VERSION ""

NS_ :

BS_:

BU_:

BO_ 933 DRIVE_SP: 2 Vector__XXX
	SG_ speed_sp : 0|16@1- (1,0) [0|31402] "cmd" Vector__XXX

BO_ 934 STEER_SP: 2 Vector__XXX
	SG_ speed_sp : 0|16@1- (1,0) [0|31402] "cmd" Vector__XXX

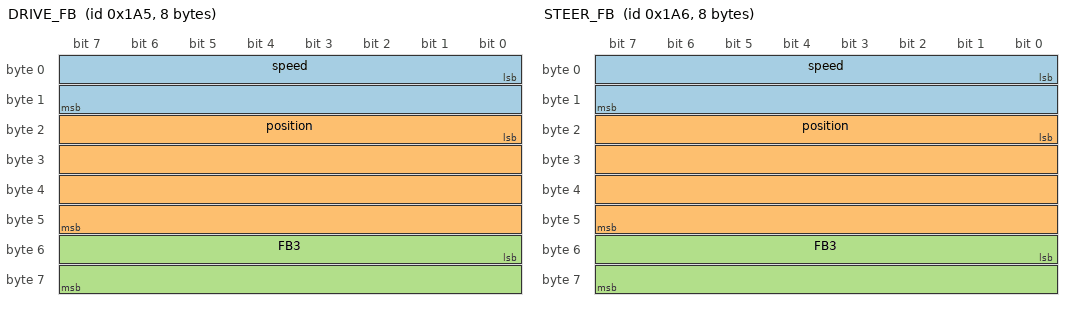
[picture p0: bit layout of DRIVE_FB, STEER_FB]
BO_ 421 DRIVE_FB: 8 Vector__XXX
	SG_ speed : 0|16@1- (1,0) [0|0] "" Vector__XXX
	SG_ position : 16|32@1- (1,0) [0|0] "" Vector__XXX
	SG_ FB3 : 48|16@1- (1,0) [0|0] "" Vector__XXX

BO_ 293 DRIVE_FB2: 6 Vector__XXX
	SG_ A : 0|8@1- (1,0) [0|0] "" Vector__XXX
	SG_ B : 24|24@1- (1,0) [0|0] "" Vector__XXX

BO_ 422 STEER_FB: 8 Vector__XXX
	SG_ speed : 0|16@1- (1,0) [0|0] "" Vector__XXX
	SG_ position : 16|32@1- (1,0) [0|0] "" Vector__XXX
	SG_ FB3 : 48|16@1- (1,0) [0|0] "" Vector__XXX

BO_ 294 STEER_FB2: 6 Vector__XXX
	SG_ A : 0|8@1- (1,0) [0|0] "" Vector__XXX
	SG_ B : 24|24@1- (1,0) [0|0] "" Vector__XXX

CM_ BO_ 933 "Driver controller set point";
CM_ SG_ 933 speed_sp "Driver speed set point";
CM_ BO_ 934 "Steering controller set point";
CM_ SG_ 934 speed_sp "Steer speed set point";
CM_ BO_ 421 "Driver controller feedback";
CM_ BO_ 422 "Steer controller feedback";
CM_ BO_ 293 "Driver controller feedback 2";
CM_ BO_ 294 "Steer controller feedback 2";

BA_DEF_ BO_  "VFrameFormat" ENUM  "StandardCAN","ExtendedCAN","reserved","J1939PG";
BA_DEF_  "DatabaseVersion" STRING ;
BA_DEF_  "BusType" STRING ;
BA_DEF_  "ProtocolType" STRING ;
BA_DEF_  "DatabaseCompiler" STRING ;
BA_DEF_DEF_  "VFrameFormat" "J1939PG";
BA_DEF_DEF_  "DatabaseVersion" "DEMO PLUS";
BA_DEF_DEF_  "BusType" "";
BA_DEF_DEF_  "ProtocolType" "";
BA_DEF_DEF_  "DatabaseCompiler" "";
BA_ "ProtocolType" "J1939";
BA_ "BusType" "CAN";
BA_ "DatabaseCompiler" "CSS ELECTRONICS (WWW.CSSELECTRONICS.COM)";
BA_ "DatabaseVersion" "1.0.0";
